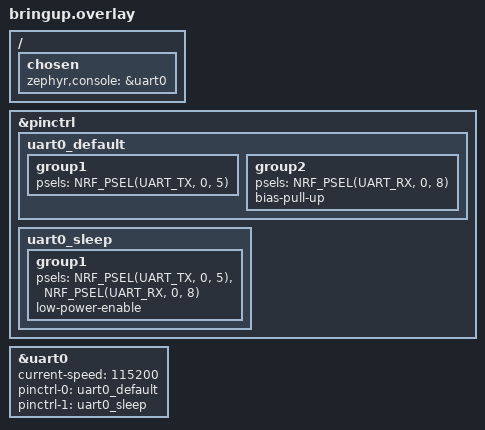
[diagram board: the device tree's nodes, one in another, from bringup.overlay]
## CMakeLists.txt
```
# SPDX-License-Identifier: Apache-2.0
cmake_minimum_required(VERSION 3.20.0)

find_package(Zephyr REQUIRED HINTS $ENV{ZEPHYR_BASE})
project(pitchiq_watch)

# The message logic is portable C that lives next to this app and is tested on a host: compiled in unchanged.
set(PQ_CORE ${CMAKE_CURRENT_SOURCE_DIR}/../core)

target_sources(app PRIVATE
  src/main.c
  src/app_glue.c
  src/ble_pq.c
  src/ui.c
  src/ui_render.c
  src/haptics.c
  src/power.c
  src/sensors.c
  src/i2c_util.c
  ${PQ_CORE}/pq_sec.c
  ${PQ_CORE}/pq_core.c
)
target_sources_ifdef(CONFIG_PQ_BRINGUP app PRIVATE src/bringup.c)
target_include_directories(app PRIVATE src ${PQ_CORE})
```

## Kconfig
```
# Application options.  The PQ_HAVE_* symbols follow the devicetree: a board that has the part gets the real code, a board
# that does not (the nRF52840 DK) gets the stub.  They are plain bools so a developer can still turn one off.
# SPDX-License-Identifier: Apache-2.0

mainmenu "PitchIQ watch firmware"

DT_CHOSEN_Z_DISPLAY := zephyr,display

config PQ_HAVE_DISPLAY
	bool "Sharp memory LCD present"
	default $(dt_chosen_enabled,$(DT_CHOSEN_Z_DISPLAY))
	select DISPLAY
	help
	  Off: the call text goes to the log instead of a screen (the DK build).

config PQ_HAVE_PMIC
	bool "nPM1300 power chip present"
	default $(dt_nodelabel_enabled,npm1300_pmic)
	help
	  Off: PQ_BATTERY_STUB reports a fixed battery level, the button is DK button 1, and there is no ship mode.

config PQ_HAVE_ACCEL
	bool "LIS2DH12 accelerometer present"
	default $(dt_nodelabel_enabled,accel)

config PQ_NPM1300_STOCK_CHARGER
	bool "Use the stock Zephyr nPM1300 charger driver (needs a full C library)"
	depends on PQ_HAVE_PMIC
	help
	  Off (default): power.c sets up and reads the charger itself through the mfd driver, same registers and the same devicetree
	  values, but without battery temperature.  On: the stock driver is used; it calls logf() so it needs picolibc (Zephyr SDK)
	  and boards/pitchiq_watch.conf must drop CONFIG_NPM13XX_CHARGER=n.  The stock path is NOT compiled in this workspace's
	  toolchain (no picolibc, newlib without retargetable locking).

config PQ_BATTERY_STUB
	bool "Fixed battery level (STUB: no fuel data on this board)"
	default y if !PQ_HAVE_PMIC
	help
	  Reports 100 % and "not charging".  Exists only so the DK build runs the same battery notification path.

config PQ_BOND_CLEAR_HOLD_MS
	int "Hold the button this long to forget the pairing (ms)"
	default 5000
	help
	  Hold the button for this long (watch: the nPM1300 SHPHLD button; DK: button 1) with the watch awake.  The bond is
	  removed, advertising reopens to any phone and a new passkey is shown at the next pairing.  Must stay below the
	  nPM1300 hardware reset hold (10 s).

config PQ_LOW_BATTERY_PCT
	int "Battery percent at or below which the watch shuts down (ship mode)"
	default 3
	depends on PQ_HAVE_PMIC

config PQ_LIGHT_ON_MOTION
	bool "Turn the frontlight on for a moment when the wrist moves"
	default y
	depends on PQ_HAVE_ACCEL

config PQ_BRINGUP
	bool "Bring-up build: UART log, PMIC/accelerometer/motor/passkey diagnostics (rev E)"
	default n
	help
	  Off (default): nothing changes, no code is added.  On (app/bringup.conf + app/bringup.overlay): src/bringup.c logs the boot
	  line, the nPM1300 state every 5 s, the LIS2DH12 every second, buzzes the motor 3 s after boot and on a short button press,
	  and logs the BLE passkey.  Needs uart0 on P0.05 (TX) / P0.08 (RX) from the overlay.

config PQ_FW_VERSION
	string "Firmware version string printed by the bring-up boot line"
	default "revE-0.1"
	depends on PQ_BRINGUP

source "Kconfig.zephyr"
```

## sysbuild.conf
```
# MCUboot with swap-using-move: no scratch partition (see the board's flash layout).  Signing uses MCUboot's default
# development key until a real key is set: see README.
SB_CONFIG_BOOTLOADER_MCUBOOT=y
SB_CONFIG_MCUBOOT_MODE_SWAP_USING_MOVE=y
SB_CONFIG_BOOT_SIGNATURE_TYPE_ECDSA_P256=y
```

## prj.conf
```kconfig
# PitchIQ watch firmware: configuration common to every board.  Board specifics are in boards/<board>.conf.
# SPDX-License-Identifier: Apache-2.0

# ---- logging over SEGGER RTT only (no UART, no console, no shell) ----
CONFIG_LOG=y
CONFIG_LOG_BACKEND_RTT=y
CONFIG_LOG_BACKEND_UART=n
CONFIG_USE_SEGGER_RTT=y
CONFIG_CONSOLE=n
CONFIG_UART_CONSOLE=n
CONFIG_SHELL=n
CONFIG_LOG_MODE_DEFERRED=y
CONFIG_LOG_DEFAULT_LEVEL=3

# ---- the single thread that runs the core is the system work queue ----
CONFIG_SYSTEM_WORKQUEUE_STACK_SIZE=2560
CONFIG_MAIN_STACK_SIZE=1536
CONFIG_HW_STACK_PROTECTION=y

# ---- peripherals ----
CONFIG_GPIO=y
CONFIG_I2C=y
CONFIG_SPI=y
CONFIG_PWM=y
CONFIG_SENSOR=y
CONFIG_REGULATOR=y
CONFIG_ASSERT=n

# ---- Bluetooth: open-source Zephyr controller and host, LE Secure Connections only ----
CONFIG_BT=y
CONFIG_BT_PERIPHERAL=y
CONFIG_BT_MAX_CONN=1
CONFIG_BT_SMP=y
CONFIG_BT_SMP_SC_ONLY=y
CONFIG_BT_SMP_ENFORCE_MITM=y
CONFIG_BT_BONDABLE=y
CONFIG_BT_MAX_PAIRED=1
CONFIG_BT_SETTINGS=y
CONFIG_BT_PRIVACY=y
CONFIG_BT_FILTER_ACCEPT_LIST=y
CONFIG_BT_DEVICE_NAME="PitchIQ"
CONFIG_BT_DEVICE_NAME_DYNAMIC=y
CONFIG_BT_DEVICE_NAME_MAX=24
CONFIG_BT_BAS=y
# A larger ATT MTU makes firmware update quick; the 20-byte PitchIQ messages do not need it.
CONFIG_BT_L2CAP_TX_MTU=247
CONFIG_BT_BUF_ACL_RX_SIZE=251
CONFIG_BT_BUF_ACL_TX_SIZE=251
CONFIG_BT_CTLR_DATA_LENGTH_MAX=251
# Ask the phone for a 20 ms interval, as the JS app did.
CONFIG_BT_GAP_AUTO_UPDATE_CONN_PARAMS=y
CONFIG_BT_PERIPHERAL_PREF_MIN_INT=16
CONFIG_BT_PERIPHERAL_PREF_MAX_INT=16
CONFIG_BT_PERIPHERAL_PREF_LATENCY=0
# Supervision timeout 6 s (600 x 10 ms): rides through a body-block fade; also the largest value iOS accepts.  RF review 6.
CONFIG_BT_PERIPHERAL_PREF_TIMEOUT=600
# RF review 7/8: 1M PHY only (2M costs about 3 dB and gains nothing for 20-byte messages), +8 dBm, connection RSSI logged.
CONFIG_BT_CTLR_PHY_2M=n
CONFIG_BT_CTLR_TX_PWR_PLUS_8=y
CONFIG_BT_CTLR_CONN_RSSI=y

# ---- bonds survive reset: settings in NVS on the "storage" partition (both boards have one, outside the MCUboot slots) ----
# Firmware review 1: without a backend Zephyr silently picks CONFIG_SETTINGS_NONE and every reset forgets the bond.
# The sector count must fit the partition: 8 x 4 KB on the DK (32 KB), 4 x 4 KB on the watch (16 KB, see boards/pitchiq_watch.conf).
CONFIG_FLASH=y
CONFIG_FLASH_MAP=y
CONFIG_NVS=y
CONFIG_SETTINGS=y
CONFIG_SETTINGS_NVS=y

# ---- watchdog (fed from the 1 s tick in app_glue.c) and cold reboot on a fatal error (main.c) ----
CONFIG_WATCHDOG=y
CONFIG_REBOOT=y
CONFIG_HWINFO=y

# ---- firmware update: mcumgr SMP over Bluetooth, authenticated link only, MCUboot image confirm ----
CONFIG_BOOTLOADER_MCUBOOT=y
CONFIG_NET_BUF=y
CONFIG_ZCBOR=y
CONFIG_CRC=y
CONFIG_STREAM_FLASH=y
CONFIG_MCUMGR=y
CONFIG_MCUMGR_GRP_IMG=y
CONFIG_MCUMGR_GRP_OS=y
CONFIG_MCUMGR_GRP_OS_MCUMGR_PARAMS=y
CONFIG_IMG_MANAGER=y
CONFIG_MCUMGR_TRANSPORT_BT=y
CONFIG_MCUMGR_TRANSPORT_BT_PERM_RW_AUTHEN=y
CONFIG_MCUMGR_MGMT_NOTIFICATION_HOOKS=y
CONFIG_MCUMGR_TRANSPORT_NETBUF_SIZE=1024
CONFIG_MCUMGR_TRANSPORT_BT_REASSEMBLY=y
CONFIG_MCUMGR_TRANSPORT_WORKQUEUE_STACK_SIZE=3072
CONFIG_THREAD_MONITOR=n
```

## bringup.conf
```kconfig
# Rev E bring-up variant.  Used with: -DEXTRA_CONF_FILE=bringup.conf -DEXTRA_DTC_OVERLAY_FILE=bringup.overlay
# Adds the UART log on P0.05 (TX) / P0.08 (RX), keeps RTT, and turns on src/bringup.c.  Not part of the normal build.
CONFIG_PQ_BRINGUP=y
# The board defconfig turns SERIAL/CONSOLE off; the overlay enables uart0, this makes it the console and a log backend.
CONFIG_SERIAL=y
CONFIG_CONSOLE=y
CONFIG_UART_CONSOLE=y
CONFIG_LOG_BACKEND_UART=y
# RTT stays on (CONFIG_LOG_BACKEND_RTT / CONFIG_USE_SEGGER_RTT from prj.conf).
# Longer logs: the 1 s and 5 s lines plus normal output.
CONFIG_LOG_BUFFER_SIZE=2048
```

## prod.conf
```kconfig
# Production hardening, NOT part of the default build.  Use it as an extra conf file:
#   west build ... -- -DEXTRA_CONF_FILE=prod.conf -DSB_EXTRA_CONF_FILE=sysbuild_prod.conf -Dmcuboot_EXTRA_CONF_FILE=sysbuild/mcuboot_prod.conf
# See README "Production build".  The unlocked bring-up build stays the default.
# SPDX-License-Identifier: Apache-2.0

# Lock the debug port (APPROTECT firmware branch) at every boot.  Recovery is still possible with a full chip erase through the
# CTRL-AP (nrfjprog --recover) on the SWD programming pads (rev C: SWD only, no charge pad); an erase wipes the bonds and the game key by design.
# (CONFIG_NRF_APPROTECT_USER_HANDLING is not available on the nRF52 series, so there is nothing to turn off.)
CONFIG_NRF_APPROTECT_LOCK=y

# The image version is what MCUboot compares for downgrade prevention (the version must rise with every release).
CONFIG_MCUBOOT_IMGTOOL_SIGN_VERSION="1.0.0+0"
```

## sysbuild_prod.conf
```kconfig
# Production sysbuild options (extra conf file, not in the default build): the project's own signing key.
# The private key lives OUTSIDE the repository; generate it with imgtool (README, "Production build").  Replace the path
# placeholder below, or pass -DSB_CONFIG_BOOT_SIGNATURE_KEY_FILE=\"/path/key.pem\" on the west command line.
# SPDX-License-Identifier: Apache-2.0
SB_CONFIG_BOOT_SIGNATURE_KEY_FILE="/CHANGE/ME/outside/repo/pitchiq_signing_key.pem"
```

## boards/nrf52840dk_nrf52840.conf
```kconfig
# nRF52840 DK build: no console UART (the DK's UART console would conflict with nothing, but the log is RTT as on the
# watch, so the same RTT viewer works for both).  The call text is logged by ui.c, so make sure those lines are visible.
CONFIG_LOG_DEFAULT_LEVEL=3
CONFIG_PQ_BOND_CLEAR_HOLD_MS=5000
```

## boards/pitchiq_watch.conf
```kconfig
# PitchIQ watch rev C.  The stock nPM13xx charger driver needs a full C library (logf); see CONFIG_PQ_NPM1300_STOCK_CHARGER in
# Kconfig.  Remove this line and turn that option on when building with the Zephyr SDK (picolibc).
CONFIG_NPM13XX_CHARGER=n

# Accelerometer interrupt handled on the system work queue (the DK has no accelerometer, so this lives here).
CONFIG_LIS2DH_TRIGGER_GLOBAL_THREAD=y

# Settings (bonds): the watch's storage partition is 16 KB = 4 erase sectors (pitchiq_watch.dts).
CONFIG_SETTINGS_NVS_SECTOR_COUNT=4
```

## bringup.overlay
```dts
/* Rev E bring-up: uart0 on the two top-side test pads, 115200 8N1, no flow control.  P0.05 = TX, P0.08 = RX
 * (the numbers are written out here on purpose; they are the two new rev E pads, not in pitchiq_watch-pinctrl.dtsi). */
&pinctrl {
	uart0_default: uart0_default {
		group1 {
			psels = <NRF_PSEL(UART_TX, 0, 5)>;
		};
		group2 {
			psels = <NRF_PSEL(UART_RX, 0, 8)>;
			bias-pull-up;
		};
	};

	uart0_sleep: uart0_sleep {
		group1 {
			psels = <NRF_PSEL(UART_TX, 0, 5)>,
				<NRF_PSEL(UART_RX, 0, 8)>;
			low-power-enable;
		};
	};
};

&uart0 {
	status = "okay";
	current-speed = <115200>;
	pinctrl-0 = <&uart0_default>;
	pinctrl-1 = <&uart0_sleep>;
	pinctrl-names = "default", "sleep";
};

/ {
	chosen {
		zephyr,console = &uart0;
	};
};
```

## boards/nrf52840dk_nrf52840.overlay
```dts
/*
 * nRF52840 DK stand-in for the watch.  The DK has no LCD, accelerometer or power chip, so those parts are
 * compiled out (Kconfig PQ_HAVE_* follow the devicetree) and these DK parts take their places:
 *   LED 1 (P0.13)  = the vibration motor: on for the buzz     (alias pq-buzz)
 *   LED 2 (P0.14)  = the frontlight                           (alias pq-light)
 *   button 1 (P0.11) = the watch button (SHPHLD): a press lights LED 2, a 5 s hold forgets the pairing
 * The call text goes to the log (RTT) instead of a screen.
 */
/ {
	aliases {
		pq-buzz = &led0;
		pq-light = &led1;
	};
};
```

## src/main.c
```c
/*
 * PitchIQ watch rev C firmware: the pitch-call display and receiver.  Start-up order matters little; every module reports
 * its own failure and the watch still tries to come up (a dead accelerometer must not stop it showing calls), but the
 * firmware update is only confirmed when everything essential worked (see app_glue.c).
 */
#include <zephyr/fatal.h>
#include <zephyr/kernel.h>
#include <zephyr/sys/reboot.h>
#include <zephyr/drivers/hwinfo.h>
#include <zephyr/logging/log.h>
#include <zephyr/logging/log_ctrl.h>

#include "pq_app.h"

LOG_MODULE_REGISTER(main, LOG_LEVEL_INF);

void app_glue_init(void);
void app_glue_set_healthy(bool ok);
void app_wdt_init(void);

/* A fatal error (hard fault, stack overflow, assert, kernel panic) must not freeze the watch with a stale screen and a dead
 * radio: note the reason in a RAM word that survives the reset and cold reboot (firmware review 2).  Zephyr's default handler
 * halts forever.  The watchdog covers hangs that do not reach here.
 *
 * Reboot-loop guard: fatal_magic holds a tag in its upper 24 bits ("PQF") and the number of CONSECUTIVE fatal resets in its low
 * byte.  The count is cleared only by app_boot_stable() once an image has run 60 s, so a fault that strikes again right after
 * every boot is counted.  At FATAL_MAX the handler does not reboot: it parks the chip (see fatal_park()).  A power cycle (the
 * nPM1300 button-hold reset) clears RAM and so the count; the tag makes random power-up RAM look like "no fatal error" (a 1 in
 * 16 million chance of a false match). */
#define FATAL_TAG 0x50514600U /* "PQF" + count byte */
#define FATAL_TAG_MASK 0xffffff00U
#define FATAL_MAX 3
static uint32_t __noinit fatal_magic;
static uint32_t __noinit fatal_reason;

static uint32_t fatal_count(void) {
  return (fatal_magic & FATAL_TAG_MASK) == FATAL_TAG ? (fatal_magic & 0xffU) : 0U;
}

void app_boot_stable(void) {
  if (fatal_magic != 0U) {
    fatal_magic = 0U;
  }
}

#if defined(CONFIG_SOC_SERIES_NRF52)
#include <nrfx.h>
#endif
#if defined(CONFIG_SOC_SERIES_NRF52) && defined(CONFIG_PQ_HAVE_PMIC)
#define PQ_MOTOR_PIN 11 /* must match PQ_PIN_MOTOR_PWM in pitchiq_watch-pinctrl.dtsi */
#endif

/* Low-power halt: nothing runs and nothing can wake the CPU except the RTC compare event used below.  The nRF52 watchdog cannot
 * be stopped once started (and "pause in sleep" would make it useless in normal operation), so it is fed by register write every
 * 4 s from a WFE loop woken by an RTC1 compare EVENT (no interrupt needed).  The motor pin is forced low first so the motor
 * cannot be left running, the radio and the HF clock are stopped.  ASSUMPTION: written from the nRF52 reference manual, never
 * run on hardware; the display keeps its last picture (its own power is not switched). */
static void fatal_park(void) {
  (void)arch_irq_lock();
#if defined(CONFIG_SOC_SERIES_NRF52)
  for (unsigned i = 0; i < ARRAY_SIZE(NVIC->ICER); i++) {
    NVIC->ICER[i] = 0xffffffffU;
  }
#if defined(PQ_MOTOR_PIN)
  NRF_PWM1->ENABLE = 0;
  NRF_P0->DIRSET = BIT(PQ_MOTOR_PIN);
  NRF_P0->OUTCLR = BIT(PQ_MOTOR_PIN);
#endif
  NRF_RADIO->TASKS_DISABLE = 1;
  NRF_CLOCK->TASKS_HFCLKSTOP = 1;
  NRF_RTC1->EVTENSET = RTC_EVTENSET_COMPARE0_Msk;
  for (;;) {
    NRF_WDT->RR[0] = WDT_RR_RR_Reload;
    NRF_RTC1->EVENTS_COMPARE[0] = 0;
    NRF_RTC1->CC[0] = (NRF_RTC1->COUNTER + 4U * 32768U) & 0xffffffU; /* 4 s on the 32.768 kHz clock */
    while (NRF_RTC1->EVENTS_COMPARE[0] == 0) {
      __WFE();
    }
  }
#else
  for (;;) {
  }
#endif
}

void k_sys_fatal_error_handler(unsigned int reason, const struct arch_esf *esf) {
  ARG_UNUSED(esf);
  uint32_t n = fatal_count() + 1U;
  fatal_reason = reason;
  fatal_magic = FATAL_TAG | (n > 0xffU ? 0xffU : n);
  LOG_PANIC();
  if (n >= FATAL_MAX) {
    fatal_park();
    CODE_UNREACHABLE;
  }
  sys_reboot(SYS_REBOOT_COLD);
  CODE_UNREACHABLE;
}

int main(void) {
  app_wdt_init();
  LOG_INF("PitchIQ watch firmware starting");
  uint32_t cause = 0;
  bool have_cause = hwinfo_get_reset_cause(&cause) == 0;
  if (have_cause) {
    LOG_INF("reset cause 0x%08x (RESETREAS)", cause);
    (void)hwinfo_clear_reset_cause();
  }
  if (IS_ENABLED(CONFIG_PQ_BRINGUP)) {
    bringup_boot(have_cause, cause);
  }
  if (fatal_count()) {
    LOG_ERR("previous run ended in a fatal error, reason %u, %u consecutive (halt at %d)", fatal_reason, fatal_count(), FATAL_MAX);
  }
  /* fatal_magic is NOT cleared here: app_boot_stable() clears it after 60 s so the count spans consecutive resets. */
  bool essential = true;

  /* The screen, the buzzer and Bluetooth are essential: without them the watch cannot do its job. */
  if (ui_init()) {
    LOG_ERR("ui_init failed");
    essential = false;
  }
  if (haptics_init()) {
    LOG_ERR("haptics_init failed");
    essential = false;
  }
  /* Power and sensors are not: report and carry on. */
  if (power_init()) {
    LOG_ERR("power_init failed: no battery data, no button");
  }
  if (sensors_init()) {
    LOG_ERR("sensors_init failed: no motion light");
  }

  /* Start the glue before Bluetooth so the first connection event finds a running core. */
  app_glue_init();
  if (ble_pq_init()) {
    LOG_ERR("ble_pq_init failed");
    essential = false;
  }
  if (!essential) {
    /* The glue keeps running (the image is not confirmed, so an update would roll back on the next reset). */
    LOG_ERR("start-up incomplete");
  }
  app_glue_set_healthy(essential);
  if (IS_ENABLED(CONFIG_PQ_BRINGUP)) {
    bringup_start();
  }
  return 0;
}
```

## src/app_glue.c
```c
/*
 * app_glue.c - binds the portable core (struct pq_io) to the hardware modules and runs it.
 *
 * ONE THREAD touches the core: everything (writes, connect/disconnect, buttons, the 1 s tick) is queued by app_post() and
 * handled on the system work queue, so the core needs no locking and its callbacks (draw, buzz, notify) may block briefly.
 *
 * Also here: the button gestures, the battery receipts, the low-battery shutdown, the idle policy hook and the MCUboot
 * image confirmation.
 *
 * Firmware update and rollback: images are written to slot 1 by mcumgr over the bonded Bluetooth link.  MCUboot swaps them
 * (swap-using-move) at the next reset as a TEST: the new image is not permanent until it calls boot_write_img_confirmed().
 * This file calls it only when the image has run 15 s and its own start-up (screen, Bluetooth advertising) all worked.  If
 * the new image crashes, hangs or cannot start Bluetooth, nobody confirms it, and the next reset (the 8 s watchdog resets a hung
 * image by itself; otherwise the button hold reset of the nPM1300 or a power cycle) makes MCUboot swap the old image back.
 */
#include <stdio.h>
#include <string.h>

#include <zephyr/dfu/mcuboot.h>
#include <zephyr/device.h>
#include <zephyr/devicetree.h>
#include <zephyr/drivers/watchdog.h>
#include <zephyr/kernel.h>
#include <zephyr/logging/log.h>

#include "pq_app.h"
#include "pq_core.h"

LOG_MODULE_REGISTER(glue, LOG_LEVEL_INF);

#define TICK_MS 1000
#define BATTERY_MS 60000
#define CONFIRM_AFTER_MS 15000
#define NOTICE_MS 3000

K_MSGQ_DEFINE(evt_q, sizeof(struct app_evt), 16, 4);

static struct pq_core core;
static struct pq_io core_io;
static atomic_t glue_ready; /* the core is initialised: events queued earlier wait until then (firmware review 7) */

/* All work items are defined statically so no interrupt, callback or early event can submit an uninitialised one. */
static void drain(struct k_work *w);
static void tick(struct k_work *w);
static void hold_fired(struct k_work *w);
static void notice_done(struct k_work *w);
#if defined(CONFIG_PQ_LOW_BATTERY_PCT)
static void lowbat_fired(struct k_work *w);
#endif
static K_WORK_DEFINE(evt_work, drain);
static K_WORK_DELAYABLE_DEFINE(tick_work, tick);
static K_WORK_DELAYABLE_DEFINE(hold_work, hold_fired);
static K_WORK_DELAYABLE_DEFINE(notice_work, notice_done);
#if defined(CONFIG_PQ_LOW_BATTERY_PCT)
static K_WORK_DELAYABLE_DEFINE(lowbat_work, lowbat_fired);
#endif
static atomic_t dropped;
static bool need_battery; /* the coach's app is subscribed by its first write: answer it with a battery receipt */
static uint32_t since_battery;
static bool healthy;
static bool confirmed;
static bool identity_warned;
static bool was_idle;
#if defined(CONFIG_PQ_LOW_BATTERY_PCT)
static uint8_t low_count;
#endif

/* ------------------------------------------------------------------------------------------ watchdog */

#define WDT_TIMEOUT_MS 8000
#if DT_NODE_HAS_STATUS_OKAY(DT_ALIAS(watchdog0))
static const struct device *const wdt = DEVICE_DT_GET(DT_ALIAS(watchdog0));
static int wdt_chan = -1;

/* Called first thing in main().  Fed from tick() on the system work queue: a hung work queue (the thread that runs the core,
 * the radio callbacks' consumer and mcumgr's confirm) lets it expire and the chip resets (firmware review 2). */
void app_wdt_init(void) {
  if (!device_is_ready(wdt)) {
    LOG_ERR("watchdog not ready");
    return;
  }
  struct wdt_timeout_cfg cfg = {
      .window = {.min = 0, .max = WDT_TIMEOUT_MS},
      .callback = NULL,
      .flags = WDT_FLAG_RESET_SOC,
  };
  wdt_chan = wdt_install_timeout(wdt, &cfg);
  if (wdt_chan < 0 || wdt_setup(wdt, WDT_OPT_PAUSE_HALTED_BY_DBG)) {
    LOG_ERR("watchdog setup failed (%d)", wdt_chan);
    wdt_chan = -1;
    return;
  }
  LOG_INF("watchdog armed: %d ms", WDT_TIMEOUT_MS);
}
static void wdt_kick(void) {
  if (wdt_chan >= 0) {
    (void)wdt_feed(wdt, wdt_chan);
  }
}
/* Also fed by pq_i2c_recover() after every failed I2C try: the boot-time I2C set-up (charger registers, accelerometer) can take
 * longer than 8 s when the bus is stuck (each access is 3 tries with a bus recovery between, and there are about 15 of them),
 * and a stuck bus must not turn into a reset loop.  Every one of those loops is bounded, so a real hang still trips the dog. */
void app_wdt_feed(void) {
  wdt_kick();
}
#else
void app_wdt_init(void) {}
void app_wdt_feed(void) {}
static void wdt_kick(void) {}
#endif

/* ------------------------------------------------------------------------------------------ io for the core */

static void io_draw(void *u, const struct pq_view *v) {
  ARG_UNUSED(u);
  ui_show(v);
}
static void io_buzz(void *u, enum pq_buzz_kind k) {
  ARG_UNUSED(u);
  haptics_buzz(k);
}
static void io_light(void *u) {
  ARG_UNUSED(u);
  ui_light();
}
static void io_notify(void *u, const uint8_t *b, size_t n) {
  ARG_UNUSED(u);
  /* Receipts go only to a secure link: nothing is sent to a peer that is not the paired coach. */
  if (ble_pq_link_secure()) {
    (void)ble_pq_notify(b, n);
  }
}
static uint64_t io_now(void *u) {
  ARG_UNUSED(u);
  return (uint64_t)k_uptime_get();
}
static bool io_secure(void *u) {
  ARG_UNUSED(u);
  return ble_pq_link_secure();
}

/* ------------------------------------------------------------------------------------------ battery */

static void battery_report(bool send) {
  struct power_status p;
  if (power_sample(&p) || !p.valid) {
    LOG_WRN("battery not readable");
    return;
  }
  ble_pq_battery_level(p.pct);
  LOG_INF("battery %u mV %u %%%s%s%s", p.mv, p.pct, p.charging ? " charging" : "", p.vbus ? " vbus" : "", p.stub ? " (STUB)" : "");
  if (send) {
    char t[8];
    int n = snprintf(t, sizeof(t), "B%u", p.pct);
    io_notify(NULL, (const uint8_t *)t, (size_t)n);
  }
#if defined(CONFIG_PQ_LOW_BATTERY_PCT)
  if (!p.stub && !p.charging && !p.vbus && p.pct <= CONFIG_PQ_LOW_BATTERY_PCT) {
    if (++low_count >= 3) { /* three readings in a row, a minute apart: not a load dip */
      LOG_ERR("battery empty: shutting down");
      ui_notice("LOW", "BATTERY");
      /* Not k_sleep(): that would block the system work queue (events, notify, mcumgr, the tick) for 2 s. */
      k_work_schedule(&lowbat_work, K_SECONDS(2));
    }
  } else {
    low_count = 0;
  }
#endif
}

#if defined(CONFIG_PQ_LOW_BATTERY_PCT)
static void lowbat_fired(struct k_work *w) {
  ARG_UNUSED(w);
  power_ship();
}
#endif

/* ------------------------------------------------------------------------------------------ policy hook */

/* Called when the wrist has been still for 30 s (idle = true) and when it moves again.  v1 only logs; a power policy
 * (dim the panel, slow the connection interval) would go here.  Override by defining it elsewhere. */
__weak void pq_policy_idle_changed(bool idle) {
  LOG_INF("idle policy hook: %s", idle ? "idle" : "active");
}

/* ------------------------------------------------------------------------------------------ work */

#define STABLE_AFTER_MS 60000 /* a boot that survives this long is not part of a fatal-error loop (main.c) */

static void tick(struct k_work *w) {
  ARG_UNUSED(w);
  wdt_kick();
  if (k_uptime_get() > STABLE_AFTER_MS) {
    app_boot_stable();
  }
  pq_core_tick(&core);

  since_battery += TICK_MS;
  if (since_battery >= BATTERY_MS) {
    since_battery = 0;
    battery_report(ble_pq_connected());
  }

  bool idle = sensors_idle();
  if (idle != was_idle) {
    was_idle = idle;
    pq_policy_idle_changed(idle);
  }

  if (!confirmed && healthy && k_uptime_get() > CONFIRM_AFTER_MS && (ble_pq_adv_running() || ble_pq_connected())) {
    /* Board identity (QA review 6): the PMIC and the accelerometer must answer on the bus.  A wrong-board image (the DK
     * image on a watch, a watch image on other hardware) is not confirmed and MCUboot reverts it at the next reset. */
    if (!power_identity_ok() || !sensors_identity_ok()) {
      if (!identity_warned) {
        identity_warned = true;
        LOG_ERR("board identity check failed: image NOT confirmed");
      }
    } else {
      int rc = boot_write_img_confirmed();
      LOG_INF("image confirmed: %d", rc);
      confirmed = rc == 0 || rc == -EALREADY;
    }
  }
  k_work_schedule(&tick_work, K_MSEC(TICK_MS));
}

static void hold_fired(struct k_work *w) {
  ARG_UNUSED(w);
  LOG_WRN("button held: forgetting the pairing");
  ble_pq_clear_bonds();
  /* End the session AND the key: the core has no separate wipe call, so re-initialise it (memset, key gone) and redraw. */
  pq_core_init(&core, &core_io);
  struct pq_view v;
  pq_core_view(&core, &v);
  ui_show(&v);
  ui_notice("PAIRING", "CLEARED");
  haptics_buzz(PQ_BUZZ_CHANGED);
  k_work_reschedule(&notice_work, K_MSEC(NOTICE_MS));
}

static void notice_done(struct k_work *w) {
  ARG_UNUSED(w);
  ui_notice_clear();
}

static void handle(const struct app_evt *e) {
  switch (e->type) {
  case EVT_WRITE:
    pq_core_on_write(&core, e->data, e->len);
    if (need_battery) {
      need_battery = false;
      battery_report(true);
    }
    break;
  case EVT_CONNECTED:
    pq_core_on_connect(&core);
    need_battery = true;
    since_battery = 0;
    break;
  case EVT_DISCONNECTED:
    pq_core_on_disconnect(&core);
    need_battery = false;
    break;
  case EVT_SECURITY:
    break;
  case EVT_PASSKEY:
    ui_set_pair_code(e->value);
    ui_light();
    break;
  case EVT_PAIR_END:
    ui_set_pair_code(0);
    break;
  case EVT_BTN_PRESS:
    ui_light();
    k_work_reschedule(&hold_work, K_MSEC(CONFIG_PQ_BOND_CLEAR_HOLD_MS));
    break;
  case EVT_BTN_RELEASE:
    if (IS_ENABLED(CONFIG_PQ_BRINGUP) && k_work_delayable_busy_get(&hold_work) != 0) {
      bringup_button_short(); /* released before the hold timer fired: a short press */
    }
    (void)k_work_cancel_delayable(&hold_work);
    break;
  case EVT_CHARGER:
    battery_report(ble_pq_connected());
    break;
  case EVT_MOTION:
    if (IS_ENABLED(CONFIG_PQ_LIGHT_ON_MOTION)) {
      ui_light();
    }
    break;
  default:
    break;
  }
}

static void drain(struct k_work *w) {
  ARG_UNUSED(w);
  if (!atomic_get(&glue_ready)) {
    return; /* app_glue_init() submits this item again once the core exists; the events stay queued */
  }
  struct app_evt e;
  while (k_msgq_get(&evt_q, &e, K_NO_WAIT) == 0) {
    handle(&e);
  }
}

void app_post(const struct app_evt *e) {
  if (k_msgq_put(&evt_q, e, K_NO_WAIT)) {
    atomic_inc(&dropped);
    LOG_WRN("event %u dropped (queue full)", e->type);
    return;
  }
  k_work_submit(&evt_work);
}

/* Called by main() once the other modules are up, before Bluetooth starts. */
void app_glue_init(void) {
  struct pq_io io = {
      .user = NULL,
      .draw = io_draw,
      .buzz = io_buzz,
      .light = io_light,
      .notify = io_notify,
      .now_ms = io_now,
      .secure = io_secure,
  };
  core_io = io;
  pq_core_init(&core, &io);
  struct pq_view v;
  pq_core_view(&core, &v);
  ui_show(&v);
  battery_report(false);
  atomic_set(&glue_ready, 1);
  k_work_submit(&evt_work); /* events that arrived during start-up */
  k_work_schedule(&tick_work, K_MSEC(TICK_MS));
}

/* Called by main() at the end of start-up: the image may be confirmed only if everything essential worked. */
void app_glue_set_healthy(bool ok) {
  healthy = ok;
}
```

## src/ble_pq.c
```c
/*
 * ble_pq.c - the Bluetooth side: the PitchIQ GATT service, pairing and bonding, advertising, and the standard Battery
 * service (from Zephyr).  Rev C has no heart-rate sensor, so there is no Heart Rate Service.
 *
 * Service (same UUIDs as watch/bangle/pitchiq.app.js):
 *   7a1d0001-... service
 *   7a1d0002-... RX  write and write-without-response, up to 20 bytes, needs an encrypted AND authenticated link
 *   7a1d0003-... TX  read + notify, up to 20 bytes (receipts to the coach: K<id>, P, A<n>, B<pct>)
 *
 * Security: LE Secure Connections only, bondable, MITM protected: the watch is a "display only" device, so Zephyr makes the
 * phone ask for a 6-digit passkey that this file hands to the UI (a random one, new for every pairing).  After the first
 * bond the filter accept list is filled with the bonded peers and advertising only accepts connections from them.
 * Clearing the bond (button hold, app_glue.c) empties the list and reopens advertising.
 * ASSUMPTION: a phone/laptop that pairs with a random private address is matched by the controller through the resolving
 * list (CONFIG_BT_PRIVACY); only a test with the real coach app can show it.
 *
 * Nothing here talks to the pq core: events go to app_glue.c through app_post().
 */
#include <stdio.h>
#include <string.h>

#include <zephyr/bluetooth/bluetooth.h>
#include <zephyr/bluetooth/conn.h>
#include <zephyr/bluetooth/gatt.h>
#include <zephyr/bluetooth/hci.h>
#include <zephyr/bluetooth/services/bas.h>
#include <zephyr/bluetooth/uuid.h>
#include <zephyr/kernel.h>
#include <zephyr/logging/log.h>
#include <zephyr/net_buf.h>
#include <zephyr/sys/byteorder.h>
#include <zephyr/settings/settings.h>
#if IS_ENABLED(CONFIG_MCUMGR_MGMT_NOTIFICATION_HOOKS)
#include <zephyr/mgmt/mcumgr/mgmt/callbacks.h>
#endif

#include "pq_app.h"

LOG_MODULE_REGISTER(ble_pq, LOG_LEVEL_INF);

#define PQ_UUID_SVC BT_UUID_128_ENCODE(0x7a1d0001, 0x5c3e, 0x4b8f, 0x9a62, 0x2f0c8e4d1b70)
#define PQ_UUID_RX BT_UUID_128_ENCODE(0x7a1d0002, 0x5c3e, 0x4b8f, 0x9a62, 0x2f0c8e4d1b70)
#define PQ_UUID_TX BT_UUID_128_ENCODE(0x7a1d0003, 0x5c3e, 0x4b8f, 0x9a62, 0x2f0c8e4d1b70)
#define PQ_MAX_LEN 20

static struct bt_uuid_128 svc_uuid = BT_UUID_INIT_128(PQ_UUID_SVC);
static struct bt_uuid_128 rx_uuid = BT_UUID_INIT_128(PQ_UUID_RX);
static struct bt_uuid_128 tx_uuid = BT_UUID_INIT_128(PQ_UUID_TX);

static struct bt_conn *conn;      /* the one connection (CONFIG_BT_MAX_CONN=1) */
static atomic_t secure_flag;
static atomic_t adv_flag;
static bool tx_notify_on;
static uint8_t tx_val[PQ_MAX_LEN];
static uint8_t tx_len;
static char dev_name[24];
static void adv_work_fn(struct k_work *w);
static K_WORK_DELAYABLE_DEFINE(adv_work, adv_work_fn); /* static: no uninitialised use (firmware review 7) */
static void rssi_work_fn(struct k_work *w);
static K_WORK_DELAYABLE_DEFINE(rssi_work, rssi_work_fn);
#define RSSI_LOG_MS 10000

/* ------------------------------------------------------------------------------------------ GATT */

static ssize_t rx_write(struct bt_conn *c, const struct bt_gatt_attr *attr, const void *buf, uint16_t len, uint16_t offset,
                        uint8_t flags) {
  ARG_UNUSED(c);
  ARG_UNUSED(attr);
  ARG_UNUSED(flags);
  if (offset != 0) {
    return BT_GATT_ERR(BT_ATT_ERR_INVALID_OFFSET);
  }
  if (len > PQ_MAX_LEN) {
    return BT_GATT_ERR(BT_ATT_ERR_INVALID_ATTRIBUTE_LEN);
  }
  struct app_evt e = {.type = EVT_WRITE, .len = (uint8_t)len};
  memcpy(e.data, buf, len);
  app_post(&e);
  return len;
}

static ssize_t tx_read(struct bt_conn *c, const struct bt_gatt_attr *attr, void *buf, uint16_t len, uint16_t offset) {
  ARG_UNUSED(c);
  return bt_gatt_attr_read(c, attr, buf, len, offset, tx_val, tx_len);
}

static void tx_ccc_changed(const struct bt_gatt_attr *attr, uint16_t value) {
  ARG_UNUSED(attr);
  tx_notify_on = value == BT_GATT_CCC_NOTIFY;
}

/* RX write, TX read and the TX CCC all need an encrypted and authenticated link (passkey, LESC): an unbonded peer can neither
 * read sealed frames nor subscribe (firmware review 4).  Receipts are in addition only sent on a secure link (app_glue.c). */
BT_GATT_SERVICE_DEFINE(pq_svc, BT_GATT_PRIMARY_SERVICE(&svc_uuid),
                       BT_GATT_CHARACTERISTIC(&rx_uuid.uuid, BT_GATT_CHRC_WRITE | BT_GATT_CHRC_WRITE_WITHOUT_RESP,
                                              BT_GATT_PERM_WRITE_AUTHEN, NULL, rx_write, NULL),
                       BT_GATT_CHARACTERISTIC(&tx_uuid.uuid, BT_GATT_CHRC_READ | BT_GATT_CHRC_NOTIFY, BT_GATT_PERM_READ_AUTHEN,
                                              tx_read, NULL, NULL),
                       BT_GATT_CCC(tx_ccc_changed, BT_GATT_PERM_READ_AUTHEN | BT_GATT_PERM_WRITE_AUTHEN));

int ble_pq_notify(const uint8_t *data, size_t len) {
  if (len > PQ_MAX_LEN) {
    len = PQ_MAX_LEN;
  }
  memcpy(tx_val, data, len);
  tx_len = (uint8_t)len;
  if (!conn || !tx_notify_on) {
    return -ENOTCONN;
  }
  return bt_gatt_notify_uuid(conn, &tx_uuid.uuid, pq_svc.attrs, tx_val, tx_len);
}

void ble_pq_battery_level(uint8_t pct) {
  (void)bt_bas_set_battery_level(pct);
}

/* ------------------------------------------------------------------------------------------ bonds and advertising */

static void count_bond(const struct bt_bond_info *info, void *user) {
  ARG_UNUSED(info);
  (*(int *)user)++;
}

bool ble_pq_bonded(void) {
  int n = 0;
  bt_foreach_bond(BT_ID_DEFAULT, count_bond, &n);
  return n > 0;
}

static void add_to_accept_list(const struct bt_bond_info *info, void *user) {
  ARG_UNUSED(user);
  int rc = bt_le_filter_accept_list_add(&info->addr);
  if (rc) {
    LOG_ERR("accept list add: %d", rc);
  }
}

/* Advertising runs fast (100-150 ms) for ADV_FAST_S after every start so a phone finds the watch at once, then drops to a
 * 1.0-1.2 s interval, which is what the power budget assumes for an idle, unconnected watch (rev C review). */
#define ADV_FAST_S 30
static bool adv_slow;
static void adv_slow_fn(struct k_work *w);
static K_WORK_DELAYABLE_DEFINE(adv_slow_work, adv_slow_fn);

static void adv_start(void) {
  uint32_t opts = BT_LE_ADV_OPT_CONN;
  int rc;

  (void)bt_le_adv_stop();
  atomic_clear(&adv_flag);

  /* Once there is a bond only bonded peers may connect: the accept list holds them and the advertiser filters on it. */
  (void)bt_le_filter_accept_list_clear();
  if (ble_pq_bonded()) {
    bt_foreach_bond(BT_ID_DEFAULT, add_to_accept_list, NULL);
    opts |= BT_LE_ADV_OPT_FILTER_CONN;
  }

  const struct bt_data ad[] = {
      BT_DATA_BYTES(BT_DATA_FLAGS, (BT_LE_AD_GENERAL | BT_LE_AD_NO_BREDR)),
      BT_DATA(BT_DATA_NAME_COMPLETE, dev_name, strlen(dev_name)),
  };
  const struct bt_data sd[] = {
      BT_DATA_BYTES(BT_DATA_UUID128_ALL, PQ_UUID_SVC),
  };
  rc = bt_le_adv_start(adv_slow ? BT_LE_ADV_PARAM(opts, BT_GAP_ADV_SLOW_INT_MIN, BT_GAP_ADV_SLOW_INT_MAX, NULL)
                                : BT_LE_ADV_PARAM(opts, BT_GAP_ADV_FAST_INT_MIN_2, BT_GAP_ADV_FAST_INT_MAX_2, NULL),
                       ad, ARRAY_SIZE(ad), sd, ARRAY_SIZE(sd));
  if (rc) {
    LOG_ERR("advertising failed: %d (retrying)", rc);
    k_work_schedule(&adv_work, K_SECONDS(2));
    return;
  }
  atomic_set(&adv_flag, 1);
  LOG_INF("advertising as \"%s\"%s%s", dev_name, (opts & BT_LE_ADV_OPT_FILTER_CONN) ? " (bonded peers only)" : "",
          adv_slow ? ", slow" : ", fast");
  if (!adv_slow) {
    k_work_reschedule(&adv_slow_work, K_SECONDS(ADV_FAST_S));
  }
}

static void adv_work_fn(struct k_work *w) {
  ARG_UNUSED(w);
  adv_slow = false; /* every (re)start begins fast */
  adv_start();
}

static void adv_slow_fn(struct k_work *w) {
  ARG_UNUSED(w);
  if (ble_pq_adv_running() && conn == NULL) {
    adv_slow = true;
    adv_start();
  }
}

bool ble_pq_adv_running(void) {
  return atomic_get(&adv_flag) != 0;
}

void ble_pq_clear_bonds(void) {
  int rc = bt_unpair(BT_ID_DEFAULT, BT_ADDR_LE_ANY);
  LOG_WRN("bonds cleared: %d", rc);
  atomic_clear(&secure_flag);
  if (conn) {
    (void)bt_conn_disconnect(conn, BT_HCI_ERR_REMOTE_USER_TERM_CONN);
  }
  k_work_schedule(&adv_work, K_MSEC(200));
}

/* ------------------------------------------------------------------------------------------ connection and pairing */

static void update_secure(struct bt_conn *c) {
  bool s = bt_conn_get_security(c) >= BT_SECURITY_L4 && bt_le_bond_exists(BT_ID_DEFAULT, bt_conn_get_dst(c));
  atomic_set(&secure_flag, s);
}

bool ble_pq_link_secure(void) {
  return atomic_get(&secure_flag) != 0;
}

bool ble_pq_connected(void) {
  return conn != NULL;
}

static void on_connected(struct bt_conn *c, uint8_t err) {
  if (err) {
    LOG_ERR("connect failed: 0x%02x", err);
    k_work_schedule(&adv_work, K_MSEC(100)); /* a failed connect must not leave the watch deaf (firmware review 5) */
    return;
  }
  if (conn) {
    return;
  }
  conn = bt_conn_ref(c);
  k_work_schedule(&rssi_work, K_MSEC(RSSI_LOG_MS));
  atomic_clear(&adv_flag);
  /* 20 ms connection interval, no latency, 6 s supervision timeout (RF review 6; matches CONFIG_BT_PERIPHERAL_PREF_*).
   * No PHY is requested: 1M only (CONFIG_BT_CTLR_PHY_2M=n). */
  (void)bt_conn_le_param_update(c, BT_LE_CONN_PARAM(16, 16, 0, 600));
  /* Ask for the secure link right away: a bonded phone encrypts with its stored key, a new one starts pairing and the
   * passkey shows on the screen. */
  (void)bt_conn_set_security(c, BT_SECURITY_L4);
  struct app_evt e = {.type = EVT_CONNECTED};
  app_post(&e);
  LOG_INF("connected");
}

static void on_disconnected(struct bt_conn *c, uint8_t reason) {
  /* Restart advertising on EVERY disconnect, including one for a connection this file never took (firmware review 5). */
  k_work_schedule(&adv_work, K_MSEC(100));
  if (c != conn) {
    return;
  }
  (void)k_work_cancel_delayable(&rssi_work);
  LOG_INF("disconnected (0x%02x)", reason);
  atomic_clear(&secure_flag);
  tx_notify_on = false;
  bt_conn_unref(conn);
  conn = NULL;
  struct app_evt e = {.type = EVT_DISCONNECTED};
  app_post(&e);
}

/* Connection RSSI every 10 s (RF review 8): the standard HCI Read RSSI against the controller's CONFIG_BT_CTLR_CONN_RSSI. */
static void rssi_work_fn(struct k_work *w) {
  ARG_UNUSED(w);
  if (!conn) {
    return;
  }
#if IS_ENABLED(CONFIG_BT_CTLR_CONN_RSSI)
  uint16_t handle;
  struct net_buf *buf = bt_hci_cmd_alloc(K_MSEC(100));
  struct net_buf *rsp = NULL;
  if (buf && bt_hci_get_conn_handle(conn, &handle) == 0) {
    struct bt_hci_cp_read_rssi *cp = net_buf_add(buf, sizeof(*cp));
    cp->handle = sys_cpu_to_le16(handle);
    if (bt_hci_cmd_send_sync(BT_HCI_OP_READ_RSSI, buf, &rsp) == 0 && rsp) {
      struct bt_hci_rp_read_rssi *rp = (void *)rsp->data;
      LOG_INF("connection RSSI %d dBm", rp->rssi);
      net_buf_unref(rsp);
    }
  } else if (buf) {
    net_buf_unref(buf);
  }
#endif
  k_work_schedule(&rssi_work, K_MSEC(RSSI_LOG_MS));
}

static void on_security(struct bt_conn *c, bt_security_t level, enum bt_security_err err) {
  if (c != conn) {
    return;
  }
  LOG_INF("security level %d err %d", level, err);
  update_secure(c);
  struct app_evt e = {.type = EVT_SECURITY};
  app_post(&e);
}

BT_CONN_CB_DEFINE(conn_cb) = {
    .connected = on_connected,
    .disconnected = on_disconnected,
    .security_changed = on_security,
};

static void passkey_display(struct bt_conn *c, unsigned int passkey) {
  ARG_UNUSED(c);
  struct app_evt e = {.type = EVT_PASSKEY, .value = passkey};
  app_post(&e);
  LOG_INF("passkey for pairing is on the screen");
  if (IS_ENABLED(CONFIG_PQ_BRINGUP)) {
    bringup_passkey(passkey);
  }
}

static void pair_cancel(struct bt_conn *c) {
  ARG_UNUSED(c);
  struct app_evt e = {.type = EVT_PAIR_END};
  app_post(&e);
}

static struct bt_conn_auth_cb auth_cb = {
    .passkey_display = passkey_display,
    .cancel = pair_cancel,
};

static void pairing_complete(struct bt_conn *c, bool bonded) {
  LOG_INF("pairing complete, bonded %d", bonded);
  update_secure(c);
  struct app_evt e = {.type = EVT_PAIR_END};
  app_post(&e);
  e.type = EVT_SECURITY;
  app_post(&e);
}

static void pairing_failed(struct bt_conn *c, enum bt_security_err reason) {
  ARG_UNUSED(c);
  LOG_WRN("pairing failed: %d", reason);
  struct app_evt e = {.type = EVT_PAIR_END};
  app_post(&e);
}

static struct bt_conn_auth_info_cb auth_info_cb = {
    .pairing_complete = pairing_complete,
    .pairing_failed = pairing_failed,
};

/* ------------------------------------------------------------------------------------------ firmware update guard */

#if IS_ENABLED(CONFIG_MCUMGR_MGMT_NOTIFICATION_HOOKS)
/* mcumgr's Bluetooth service already needs an encrypted, authenticated link (CONFIG_MCUMGR_TRANSPORT_BT_PERM_RW_AUTHEN).
 * This hook adds "and bonded": every SMP command is refused unless the link is secure in the sense of ble_pq_link_secure(). */
static enum mgmt_cb_return smp_guard(uint32_t event, enum mgmt_cb_return prev, int32_t *rc, uint16_t *group, bool *abort_more,
                                     void *data, size_t data_size) {
  ARG_UNUSED(event);
  ARG_UNUSED(prev);
  ARG_UNUSED(group);
  ARG_UNUSED(data);
  ARG_UNUSED(data_size);
  if (ble_pq_link_secure()) {
    return MGMT_CB_OK;
  }
  *rc = MGMT_ERR_EACCESSDENIED;
  *abort_more = true;
  return MGMT_CB_ERROR_RC;
}
static struct mgmt_callback smp_guard_cb = {.callback = smp_guard, .event_id = MGMT_EVT_OP_CMD_RECV};
#endif

/* ------------------------------------------------------------------------------------------ init */

int ble_pq_init(void) {
  int rc = bt_conn_auth_cb_register(&auth_cb);
  if (rc) {
    return rc;
  }
  rc = bt_conn_auth_info_cb_register(&auth_info_cb);
  if (rc) {
    return rc;
  }
  rc = bt_enable(NULL);
  if (rc) {
    LOG_ERR("bt_enable: %d", rc);
    return rc;
  }
  if (IS_ENABLED(CONFIG_SETTINGS)) {
    rc = settings_load(); /* the bonds */
    if (rc) {
      LOG_ERR("settings_load: %d", rc);
    }
    /* Bring-up check (firmware review 1): pair, reset, and this count must still be 1.  Backend: NVS, see prj.conf. */
    int nb = 0;
    bt_foreach_bond(BT_ID_DEFAULT, count_bond, &nb);
    LOG_INF("settings loaded (%s): %d bond(s)", IS_ENABLED(CONFIG_SETTINGS_NVS) ? "NVS" : "NO PERSISTENT BACKEND", nb);
  }

  /* "PitchIQ" + the last 4 hex digits of the address, so two watches can be told apart in the chooser. */
  bt_addr_le_t addrs[CONFIG_BT_ID_MAX];
  size_t count = ARRAY_SIZE(addrs);
  bt_id_get(addrs, &count);
  if (count) {
    snprintf(dev_name, sizeof(dev_name), "PitchIQ %02X%02X", addrs[0].a.val[1], addrs[0].a.val[0]);
  } else {
    snprintf(dev_name, sizeof(dev_name), "PitchIQ");
  }
  (void)bt_set_name(dev_name);

#if IS_ENABLED(CONFIG_MCUMGR_MGMT_NOTIFICATION_HOOKS)
  mgmt_callback_register(&smp_guard_cb);
#endif
  adv_start();
  return ble_pq_adv_running() ? 0 : -EIO;
}
```

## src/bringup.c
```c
/*
 * bringup.c - rev E bring-up diagnostics.  Compiled only with CONFIG_PQ_BRINGUP (app/bringup.conf), so the normal build is
 * unchanged.  Needs neither the display nor a phone: everything goes to the log (UART on P0.05/P0.08 and RTT).
 *   boot line, nPM1300 state every 5 s, LIS2DH12 WHO_AM_I once then x/y/z every 1 s, motor buzz 3 s after boot and on a
 *   short button press, the BLE passkey, the LCD init result.
 * Compiles; not run on hardware.
 */
#include <stdio.h>

#include <zephyr/device.h>
#include <zephyr/devicetree.h>
#include <zephyr/drivers/hwinfo.h>
#include <zephyr/drivers/i2c.h>
#include <zephyr/drivers/sensor.h>
#include <zephyr/dfu/mcuboot.h>
#include <zephyr/kernel.h>
#include <zephyr/logging/log.h>

#include "pq_app.h"

LOG_MODULE_REGISTER(bringup, LOG_LEVEL_INF);

#define BUZZ_MS 300
#define BUZZ_AFTER_BOOT_MS 3000
#define TICK_MS 1000
#define PMIC_EVERY 5 /* ticks */

#if IS_ENABLED(CONFIG_PQ_HAVE_PMIC)
#include <zephyr/drivers/mfd/npm13xx.h>
static const struct device *const pmic = DEVICE_DT_GET(DT_NODELABEL(npm1300_pmic));
/* Same offsets as power.c and the stock driver (npm13xx_charger.c): charger base 0x03, ISET 0x08/0x09, status 0x34, error
 * reason 0x36; VBUSIN base 0x02, status 0x07. */
#define CHGR_BASE 0x03U
#define VBUS_BASE 0x02U
#define CHGR_ISET 0x08U
#define CHGR_CHG_STAT 0x34U
#define CHGR_ERR_REASON 0x36U
#define VBUS_STATUS 0x07U
#endif

#if IS_ENABLED(CONFIG_PQ_HAVE_ACCEL)
static const struct device *const accel = DEVICE_DT_GET(DT_NODELABEL(accel));
static const struct i2c_dt_spec accel_i2c = I2C_DT_SPEC_GET(DT_NODELABEL(accel));
#define LIS_WHO_AM_I 0x0f
#endif

static void tick(struct k_work *w);
static void boot_buzz(struct k_work *w);
static K_WORK_DELAYABLE_DEFINE(tick_work, tick);
static K_WORK_DELAYABLE_DEFINE(buzz_work, boot_buzz);
static unsigned int ticks;

static const struct {
  uint32_t flag;
  const char *name;
} RESET_NAMES[] = {{RESET_PIN, "PIN"},           {RESET_SOFTWARE, "SOFTWARE"}, {RESET_BROWNOUT, "BROWNOUT"},
                   {RESET_POR, "POR"},           {RESET_WATCHDOG, "WATCHDOG"}, {RESET_DEBUG, "DEBUG"},
                   {RESET_CPU_LOCKUP, "LOCKUP"}, {RESET_LOW_POWER_WAKE, "LPWAKE"}};

void bringup_boot(bool have_cause, uint32_t cause) {
  char names[64] = "";
  size_t n = 0;
  for (size_t i = 0; i < ARRAY_SIZE(RESET_NAMES); i++) {
    if (cause & RESET_NAMES[i].flag) {
      n += snprintf(names + n, sizeof(names) - n, "%s%s", n ? "|" : "", RESET_NAMES[i].name);
    }
  }
  LOG_INF("BOOT fw %s reset 0x%08x %s confirmed %d", CONFIG_PQ_FW_VERSION, (unsigned)cause,
          have_cause ? (names[0] ? names : "none") : "unknown", boot_is_img_confirmed() ? 1 : 0);
}

void bringup_lcd(bool ok) {
  if (ok) {
    LOG_INF("LCD init ok");
  } else {
    LOG_ERR("LCD init failed");
  }
}

void bringup_passkey(uint32_t passkey) {
  LOG_INF("PASSKEY %06u", (unsigned)(passkey % 1000000U));
}

void bringup_button_short(void) {
  LOG_INF("button short press");
  haptics_buzz_ms(BUZZ_MS);
}

static void boot_buzz(struct k_work *w) {
  ARG_UNUSED(w);
  LOG_INF("boot buzz");
  haptics_buzz_ms(BUZZ_MS);
}

static void pmic_line(void) {
#if IS_ENABLED(CONFIG_PQ_HAVE_PMIC)
  uint8_t stat = 0, err = 0, vbs = 0, iset[2] = {0, 0};
  int rc = mfd_npm13xx_reg_read(pmic, CHGR_BASE, CHGR_CHG_STAT, &stat);
  rc |= mfd_npm13xx_reg_read(pmic, CHGR_BASE, CHGR_ERR_REASON, &err);
  rc |= mfd_npm13xx_reg_read(pmic, VBUS_BASE, VBUS_STATUS, &vbs);
  rc |= mfd_npm13xx_reg_read_burst(pmic, CHGR_BASE, CHGR_ISET, iset, 2U);
  struct power_status ps;
  int prc = power_sample(&ps);
  /* ISET index = msb * 2 + lsb bit 0; current = 32 mA + (index - 16) * 2 mA (the inverse of power.c ISET_IDX). */
  unsigned int idx = (unsigned int)iset[0] * 2U + (iset[1] & 1U);
  unsigned int ma = idx >= 16U ? 32U + (idx - 16U) * 2U : 0U;
  LOG_INF("PMIC vbus %d chg_stat 0x%02x chg_err 0x%02x vbus_stat 0x%02x vbat %u mV iset %u mA (idx %u) rc %d/%d",
          prc == 0 ? (int)ps.vbus : -1, stat, err, vbs, prc == 0 ? ps.mv : 0U, ma, idx, rc, prc);
#else
  LOG_WRN("PMIC: not on this board");
#endif
}

static void accel_line(void) {
#if IS_ENABLED(CONFIG_PQ_HAVE_ACCEL)
  struct sensor_value v[3];
  int rc = sensor_sample_fetch(accel);
  if (rc == 0) {
    rc = sensor_channel_get(accel, SENSOR_CHAN_ACCEL_XYZ, v);
  }
  if (rc) {
    LOG_ERR("ACCEL read failed %d", rc);
    return;
  }
  /* m/s^2 (milli) to milli-g: x / 9.80665 */
  int32_t mg[3];
  for (int i = 0; i < 3; i++) {
    mg[i] = (int32_t)(((int64_t)sensor_value_to_milli(&v[i]) * 100000) / 980665);
  }
  LOG_INF("ACCEL mg x %d y %d z %d", (int)mg[0], (int)mg[1], (int)mg[2]);
#endif
}

static void tick(struct k_work *w) {
  ARG_UNUSED(w);
  if (ticks % PMIC_EVERY == 0) {
    pmic_line();
  }
  accel_line();
  ticks++;
  k_work_schedule(&tick_work, K_MSEC(TICK_MS));
}

void bringup_start(void) {
#if IS_ENABLED(CONFIG_PQ_HAVE_ACCEL)
  uint8_t id = 0;
  int rc = i2c_reg_read_byte_dt(&accel_i2c, LIS_WHO_AM_I, &id);
  LOG_INF("ACCEL WHO_AM_I 0x%02x at I2C 0x%02x rc %d (expect 0x33 at 0x19)%s", id, accel_i2c.addr, rc,
          (rc == 0 && id == 0x33) ? " OK" : " MISMATCH");
#endif
  k_work_schedule(&tick_work, K_MSEC(TICK_MS));
  /* "3 s after boot" counted from kernel start (k_uptime), not from this call. */
  int64_t left = BUZZ_AFTER_BOOT_MS - k_uptime_get();
  k_work_schedule(&buzz_work, K_MSEC(left > 0 ? left : 0));
}
```

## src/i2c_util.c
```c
/*
 * i2c_util.c - bus recovery for the one shared I2C bus (nPM1300, LIS2DH12 on TWIM0).  A sensor that holds SDA low
 * after an ESD hit or a reset in mid-transfer would otherwise stop the charger set-up, the button and every sensor.  The
 * retry macro PQ_I2C_RETRY (pq_app.h) calls this between tries.
 */
#include <zephyr/device.h>
#include <zephyr/devicetree.h>
#include <zephyr/drivers/i2c.h>
#include <zephyr/logging/log.h>

#include "pq_app.h"

LOG_MODULE_REGISTER(i2c_util, LOG_LEVEL_INF);

#if DT_NODE_HAS_STATUS_OKAY(DT_NODELABEL(i2c0))
int pq_i2c_recover(void) {
  const struct device *bus = DEVICE_DT_GET(DT_NODELABEL(i2c0));
  if (!device_is_ready(bus)) {
    return -ENODEV;
  }
  int rc = i2c_recover_bus(bus);
  LOG_WRN("I2C bus recovery: %d", rc);
  app_wdt_feed(); /* a stuck bus at boot must not outlast the 8 s watchdog (see app_glue.c) */
  return rc;
}
#else
int pq_i2c_recover(void) {
  return 0;
}
#endif
```
